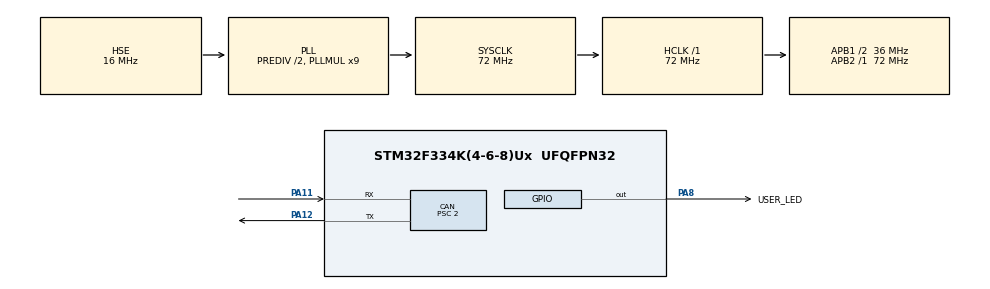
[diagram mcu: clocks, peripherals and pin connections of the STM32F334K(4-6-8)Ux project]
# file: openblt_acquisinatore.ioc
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CAN.BS1=CAN_BS1_15TQ
CAN.BS2=CAN_BS2_2TQ
CAN.CalculateBaudRate=1000000
CAN.CalculateTimeBit=1000
CAN.CalculateTimeQuantum=55.55555555555556
CAN.Prescaler=2
Mcu.Family=STM32F3
Mcu.Name=STM32F334K(4-6-8)Ux
Mcu.Package=UFQFPN32
NVIC.CAN_RX0_IRQn=true\:0\:0\:false\:false\:true\:true\:true\:true
NVIC.CAN_RX1_IRQn=true\:0\:0\:false\:false\:true\:true\:true\:true
NVIC.CAN_SCE_IRQn=true\:0\:0\:false\:false\:true\:true\:true\:true
NVIC.CAN_TX_IRQn=true\:0\:0\:false\:false\:true\:true\:true\:true
NVIC.PriorityGroup=NVIC_PRIORITYGROUP_4
NVIC.TIM2_IRQn=true\:0\:0\:false\:false\:true\:true\:true\:true
PA11.Mode=CAN_Activate
PA11.Signal=CAN_RX
PA12.Mode=CAN_Activate
PA12.Signal=CAN_TX
PA8.GPIO_Label=USER_LED
PA8.Signal=GPIO_Output
PF0\ /\ OSC_IN.Mode=HSE-External-Oscillator
PF0\ /\ OSC_IN.Signal=RCC_OSC_IN
PF1\ /\ OSC_OUT.Mode=HSE-External-Oscillator
PF1\ /\ OSC_OUT.Signal=RCC_OSC_OUT
ProjectManager.HeapSize=0x200
ProjectManager.StackSize=0x400
ProjectManager.TargetToolchain=Makefile
RCC.AHBFreq_Value=72000000
RCC.APB1CLKDivider=RCC_HCLK_DIV2
RCC.APB1Freq_Value=36000000
RCC.APB1TimFreq_Value=72000000
RCC.APB2Freq_Value=72000000
RCC.APB2TimFreq_Value=72000000
RCC.CortexFreq_Value=72000000
RCC.HCLKFreq_Value=72000000
RCC.HSE_VALUE=16000000
RCC.HSI_VALUE=8000000
RCC.PLLMUL=RCC_PLL_MUL9
RCC.PLLSourceVirtual=RCC_PLLSOURCE_HSE
RCC.RCC_PLLsource_Clock_Source_FROM_HSE=RCC_HSE_PREDIV_DIV2
RCC.SYSCLKFreq_VALUE=72000000
RCC.SYSCLKSourceVirtual=RCC_SYSCLKSOURCE_PLLCLK
TIM2.Channel-Output\ Compare1\ No\ Output=TIM_CHANNEL_1
TIM2.ClockDivision=TIM_CLOCKDIVISION_DIV4
TIM2.CounterMode=TIM_COUNTERMODE_DOWN
TIM2.OC1Preload=DISABLE
TIM2.Period=5
TIM2.Prescaler=9
VP_TIM2_VS_ClockSourceINT.Mode=Internal
VP_TIM2_VS_no_output1.Mode=Output Compare1 No Output
board=custom

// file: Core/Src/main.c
/* USER CODE BEGIN Header */
/**
  ******************************************************************************
  * @file           : main.c
  * @brief          : Main program body
  ******************************************************************************
  * @attention
  *
  * Copyright (c) 2024 STMicroelectronics.
  * All rights reserved.
  *
  * This software is licensed under terms that can be found in the LICENSE file
  * in the root directory of this software component.
  * If no LICENSE file comes with this software, it is provided AS-IS.
  *
  ******************************************************************************
  */
/* USER CODE END Header */
#include "main.h"

/* USER CODE BEGIN Includes */

#include "boot.h"

/* USER CODE END Includes */

CAN_HandleTypeDef hcan;

TIM_HandleTypeDef htim2;

void SystemClock_Config(void);
static void MX_GPIO_Init(void);
static void MX_TIM2_Init(void);
static void MX_CAN_Init(void);

/* USER CODE BEGIN 0 */

// TODO: include the crash debug stuff so that we can debug strange stuff remotely
#define CHECK_HAL_RES(res) \
    if (res != HAL_OK) {   \
        return res;        \
    }

HAL_StatusTypeDef save_configs_to_flash(float data1, float data2, uint32_t acquisinatore_version) {
    HAL_StatusTypeDef res = HAL_FLASH_Unlock();
    CHECK_HAL_RES(res);

    FLASH_EraseInitTypeDef erase_init = {
        .TypeErase = FLASH_TYPEERASE_PAGES, .PageAddress = ACQUISINATOR_CONFIG_RESERVED_ADDRESS, .NbPages = 1};
    uint32_t mem_error = 0;
    res                = HAL_FLASHEx_Erase(&erase_init, &mem_error);
    CHECK_HAL_RES(res);

    union {
        uint32_t d;
        float f;
    } flash_config_union = {.f = data1};

    res = HAL_FLASH_Program(FLASH_TYPEPROGRAM_WORD, ACQUISINATOR_CONFIG_RESERVED_ADDRESS, flash_config_union.d);
    CHECK_HAL_RES(res);

    flash_config_union.f = data2;
    res = HAL_FLASH_Program(FLASH_TYPEPROGRAM_WORD, ACQUISINATOR_CONFIG_RESERVED_ADDRESS + sizeof(data1), flash_config_union.d);
    CHECK_HAL_RES(res);

    res = HAL_FLASH_Program(
        FLASH_TYPEPROGRAM_WORD, ACQUISINATOR_CONFIG_RESERVED_ADDRESS + sizeof(data1) + sizeof(data2), acquisinatore_version);
    CHECK_HAL_RES(res);

    res = HAL_FLASH_Lock();
    CHECK_HAL_RES(res);
    return HAL_OK;
}

/* USER CODE END 0 */

int main(void)
{

  /* MCU Configuration--------------------------------------------------------*/

  /* Reset of all peripherals, Initializes the Flash interface and the Systick. */
  HAL_Init();

  /* Configure the system clock */
  SystemClock_Config();

  /* Initialize all configured peripherals */
  MX_GPIO_Init();
  MX_TIM2_Init();
  MX_CAN_Init();
  /* USER CODE BEGIN 2 */

  HAL_GPIO_WritePin(USER_LED_GPIO_Port, USER_LED_Pin, GPIO_PIN_SET);

  if (save_configs_to_flash(0.0f, 0.0f, ACQUISINATOR_ID) < HAL_OK) {
    Error_Handler();
  }

  BootInit();
  /* USER CODE END 2 */

  /* Infinite loop */
  /* USER CODE BEGIN WHILE */
  while (1)
  {
    BootTask();
    /* USER CODE END WHILE */

  }
}

void SystemClock_Config(void)
{
  RCC_OscInitTypeDef RCC_OscInitStruct = {0};
  RCC_ClkInitTypeDef RCC_ClkInitStruct = {0};

  /** Initializes the RCC Oscillators according to the specified parameters
  * in the RCC_OscInitTypeDef structure.
  */
  RCC_OscInitStruct.OscillatorType = RCC_OSCILLATORTYPE_HSE;
  RCC_OscInitStruct.HSEState = RCC_HSE_ON;
  RCC_OscInitStruct.HSEPredivValue = RCC_HSE_PREDIV_DIV2;
  RCC_OscInitStruct.HSIState = RCC_HSI_ON;
  RCC_OscInitStruct.PLL.PLLState = RCC_PLL_ON;
  RCC_OscInitStruct.PLL.PLLSource = RCC_PLLSOURCE_HSE;
  RCC_OscInitStruct.PLL.PLLMUL = RCC_PLL_MUL9;
  if (HAL_RCC_OscConfig(&RCC_OscInitStruct) != HAL_OK)
  {
    Error_Handler();
  }

  /** Initializes the CPU, AHB and APB buses clocks
  */
  RCC_ClkInitStruct.ClockType = RCC_CLOCKTYPE_HCLK|RCC_CLOCKTYPE_SYSCLK
                              |RCC_CLOCKTYPE_PCLK1|RCC_CLOCKTYPE_PCLK2;
  RCC_ClkInitStruct.SYSCLKSource = RCC_SYSCLKSOURCE_PLLCLK;
  RCC_ClkInitStruct.AHBCLKDivider = RCC_SYSCLK_DIV1;
  RCC_ClkInitStruct.APB1CLKDivider = RCC_HCLK_DIV2;
  RCC_ClkInitStruct.APB2CLKDivider = RCC_HCLK_DIV1;

  if (HAL_RCC_ClockConfig(&RCC_ClkInitStruct, FLASH_LATENCY_2) != HAL_OK)
  {
    Error_Handler();
  }
}

static void MX_CAN_Init(void)
{

  hcan.Instance = CAN;
  hcan.Init.Prescaler = 2;
  hcan.Init.Mode = CAN_MODE_NORMAL;
  hcan.Init.SyncJumpWidth = CAN_SJW_1TQ;
  hcan.Init.TimeSeg1 = CAN_BS1_15TQ;
  hcan.Init.TimeSeg2 = CAN_BS2_2TQ;
  hcan.Init.TimeTriggeredMode = DISABLE;
  hcan.Init.AutoBusOff = DISABLE;
  hcan.Init.AutoWakeUp = DISABLE;
  hcan.Init.AutoRetransmission = DISABLE;
  hcan.Init.ReceiveFifoLocked = DISABLE;
  hcan.Init.TransmitFifoPriority = DISABLE;
  if (HAL_CAN_Init(&hcan) != HAL_OK)
  {
    Error_Handler();
  }

}

static void MX_TIM2_Init(void)
{

  TIM_ClockConfigTypeDef sClockSourceConfig = {0};
  TIM_MasterConfigTypeDef sMasterConfig = {0};
  TIM_OC_InitTypeDef sConfigOC = {0};

  htim2.Instance = TIM2;
  htim2.Init.Prescaler = 9;
  htim2.Init.CounterMode = TIM_COUNTERMODE_DOWN;
  htim2.Init.Period = 5;
  htim2.Init.ClockDivision = TIM_CLOCKDIVISION_DIV4;
  htim2.Init.AutoReloadPreload = TIM_AUTORELOAD_PRELOAD_DISABLE;
  if (HAL_TIM_Base_Init(&htim2) != HAL_OK)
  {
    Error_Handler();
  }
  sClockSourceConfig.ClockSource = TIM_CLOCKSOURCE_INTERNAL;
  if (HAL_TIM_ConfigClockSource(&htim2, &sClockSourceConfig) != HAL_OK)
  {
    Error_Handler();
  }
  if (HAL_TIM_OC_Init(&htim2) != HAL_OK)
  {
    Error_Handler();
  }
  sMasterConfig.MasterOutputTrigger = TIM_TRGO_RESET;
  sMasterConfig.MasterSlaveMode = TIM_MASTERSLAVEMODE_DISABLE;
  if (HAL_TIMEx_MasterConfigSynchronization(&htim2, &sMasterConfig) != HAL_OK)
  {
    Error_Handler();
  }
  sConfigOC.OCMode = TIM_OCMODE_TIMING;
  sConfigOC.Pulse = 0;
  sConfigOC.OCPolarity = TIM_OCPOLARITY_HIGH;
  sConfigOC.OCFastMode = TIM_OCFAST_DISABLE;
  if (HAL_TIM_OC_ConfigChannel(&htim2, &sConfigOC, TIM_CHANNEL_1) != HAL_OK)
  {
    Error_Handler();
  }

}

static void MX_GPIO_Init(void)
{
  GPIO_InitTypeDef GPIO_InitStruct = {0};

  /* GPIO Ports Clock Enable */
  __HAL_RCC_GPIOF_CLK_ENABLE();
  __HAL_RCC_GPIOA_CLK_ENABLE();

  /*Configure GPIO pin Output Level */
  HAL_GPIO_WritePin(USER_LED_GPIO_Port, USER_LED_Pin, GPIO_PIN_RESET);

  /*Configure GPIO pin : USER_LED_Pin */
  GPIO_InitStruct.Pin = USER_LED_Pin;
  GPIO_InitStruct.Mode = GPIO_MODE_OUTPUT_PP;
  GPIO_InitStruct.Pull = GPIO_NOPULL;
  GPIO_InitStruct.Speed = GPIO_SPEED_FREQ_LOW;
  HAL_GPIO_Init(USER_LED_GPIO_Port, &GPIO_InitStruct);

}

void Error_Handler(void)
{
  __disable_irq();
  while (1)
  {
  }
}
